AUTOSAR XML (schema 00051)
package /TPC_Composition/Components
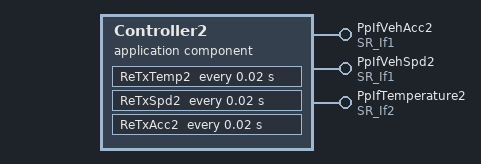
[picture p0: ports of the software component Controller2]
  application sw component type Controller2
    provide port PpIfVehAcc2: provided-interface=SR_If1, nonqueued-sender-com-spec{data-element=Acc, init-value=777}
    provide port PpIfVehSpd2: provided-interface=SR_If1, nonqueued-sender-com-spec{data-element=Spd, init-value=666}
    provide port PpIfTemperature2: provided-interface=SR_If2, queued-sender-com-spec=Temp
    behavior SWC_Controller2_InternalBehavior: supports-multiple-instantiation=true
      runnable ReTxTemp2
        data-write-access:
          access DataSendPoint_PpIfTemperature2_Temp: return-value-provision=RETURN-VALUE-PROVIDED, accessed-variable=PpIfTemperature2.Temp
      runnable ReTxSpd2
        data-write-access:
          access DataSendPoint_PpIfVehMov_Spd: return-value-provision=RETURN-VALUE-PROVIDED, accessed-variable=PpIfVehSpd2.Spd
      runnable ReTxAcc2
        data-write-access:
          access DataSendPoint_PpIfVehMov_Acc: return-value-provision=RETURN-VALUE-PROVIDED, accessed-variable=PpIfVehAcc2.Acc
      timing event EvTiTemp_20ms: start-on-event=ReTxTemp2, period=0.02
      timing event EvTiSpd_20ms: start-on-event=ReTxSpd2, period=0.02
      timing event EvTiAcc_20ms: start-on-event=ReTxAcc2, period=0.02
      port-api-options:
        port=PpIfVehAcc2, transformer-status-forwarding=TRANSFORMER-STATUS-FORWARDING, error-handling=TRANSFORMER-ERROR-HANDLING
        port=PpIfTemperature2, error-handling=TRANSFORMER-ERROR-HANDLING
